# ioADuCM302x register map
Registers are 16-bit, access not given, no defined reset value unless marked. A register's access mark holds for its fields unless they carry their own. Addresses are absolute; registers are grouped by the start of their names; [hi:lo] are bit positions; {n}, {i} and the like mark numbered series.

## RTC1
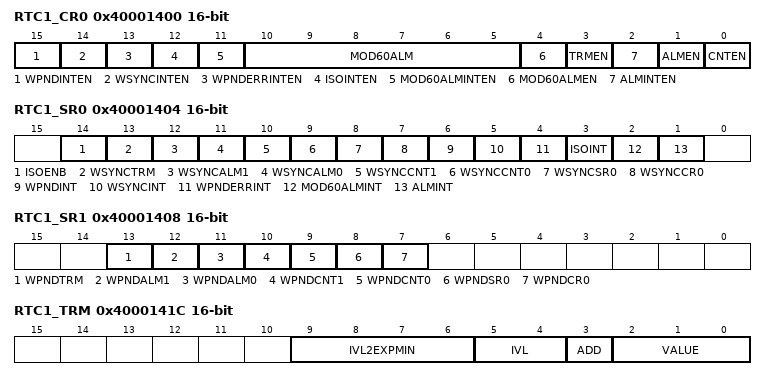
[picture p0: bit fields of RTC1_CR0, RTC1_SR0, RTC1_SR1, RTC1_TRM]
0x40001400 RTC1_CR0
  [15] WPNDINTEN, [14] WSYNCINTEN, [13] WPNDERRINTEN, [12] ISOINTEN, [11] MOD60ALMINTEN, [10:5] MOD60ALM, [4] MOD60ALMEN, [3] TRMEN, [2] ALMINTEN, [1] ALMEN, [0] CNTEN
0x40001404 RTC1_SR0
  [14] ISOENB, [13] WSYNCTRM, [12] WSYNCALM1, [11] WSYNCALM0, [10] WSYNCCNT1, [9] WSYNCCNT0, [8] WSYNCSR0, [7] WSYNCCR0, [6] WPNDINT, [5] WSYNCINT, [4] WPNDERRINT, [3] ISOINT, [2] MOD60ALMINT, [1] ALMINT
0x40001408 RTC1_SR1
  [13] WPNDTRM, [12] WPNDALM1, [11] WPNDALM0, [10] WPNDCNT1, [9] WPNDCNT0, [8] WPNDSR0, [7] WPNDCR0
0x4000140C RTC1_CNT0
0x40001410 RTC1_CNT1
0x40001414 RTC1_ALM0
0x40001418 RTC1_ALM1
0x4000141C RTC1_TRM
  [9:6] IVL2EXPMIN, [5:4] IVL, [3] ADD, [2:0] VALUE
0x40001420 RTC1_GWY
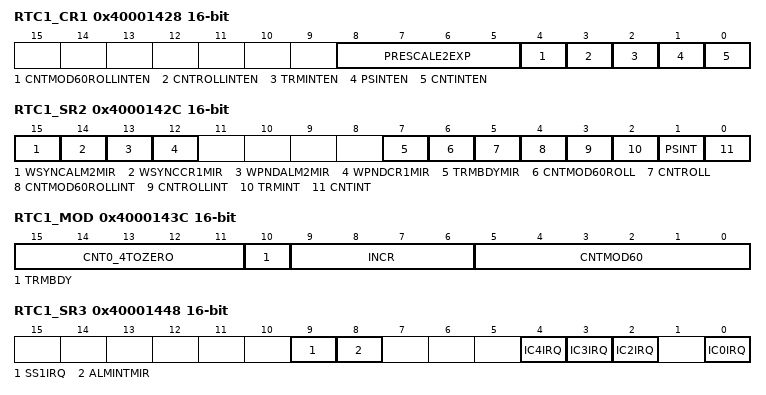
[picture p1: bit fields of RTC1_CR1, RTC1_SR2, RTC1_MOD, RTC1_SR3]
0x40001428 RTC1_CR1
  [8:5] PRESCALE2EXP, [4] CNTMOD60ROLLINTEN, [3] CNTROLLINTEN, [2] TRMINTEN, [1] PSINTEN, [0] CNTINTEN
0x4000142C RTC1_SR2
  [15] WSYNCALM2MIR, [14] WSYNCCR1MIR, [13] WPNDALM2MIR, [12] WPNDCR1MIR, [7] TRMBDYMIR, [6] CNTMOD60ROLL, [5] CNTROLL, [4] CNTMOD60ROLLINT, [3] CNTROLLINT, [2] TRMINT, [1] PSINT, [0] CNTINT
0x40001430 RTC1_SNAP0
0x40001434 RTC1_SNAP1
0x40001438 RTC1_SNAP2
  [14:0] VALUE
0x4000143C RTC1_MOD
  [15:11] CNT0_4TOZERO, [10] TRMBDY, [9:6] INCR, [5:0] CNTMOD60
0x40001440 RTC1_CNT2
  [14:0] VALUE
0x40001444 RTC1_ALM2
  [14:0] VALUE
0x40001448 RTC1_SR3
  [9] SS1IRQ, [8] ALMINTMIR, [4] IC4IRQ, [3] IC3IRQ, [2] IC2IRQ, [0] IC0IRQ
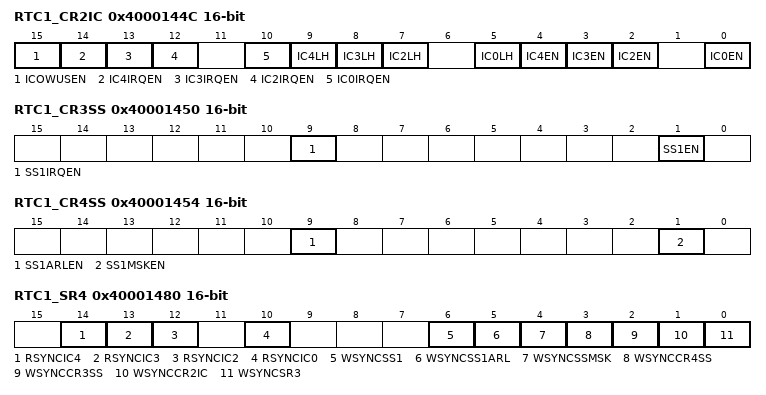
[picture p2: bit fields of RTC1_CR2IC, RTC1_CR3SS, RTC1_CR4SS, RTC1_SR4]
0x4000144C RTC1_CR2IC
  [15] ICOWUSEN, [14] IC4IRQEN, [13] IC3IRQEN, [12] IC2IRQEN, [10] IC0IRQEN, [9] IC4LH, [8] IC3LH, [7] IC2LH, [5] IC0LH, [4] IC4EN, [3] IC3EN, [2] IC2EN, [0] IC0EN
0x40001450 RTC1_CR3SS
  [9] SS1IRQEN, [1] SS1EN
0x40001454 RTC1_CR4SS
  [9] SS1ARLEN, [1] SS1MSKEN
0x40001458 RTC1_SSMSK
0x4000145C RTC1_SS1ARL
{0x4000145C+4i} RTC1_IC{i} (i=2..4)
0x40001470 RTC1_SS1
0x40001480 RTC1_SR4
  [14] RSYNCIC4, [13] RSYNCIC3, [12] RSYNCIC2, [10] RSYNCIC0, [6] WSYNCSS1, [5] WSYNCSS1ARL, [4] WSYNCSSMSK, [3] WSYNCCR4SS, [2] WSYNCCR3SS, [1] WSYNCCR2IC, [0] WSYNCSR3
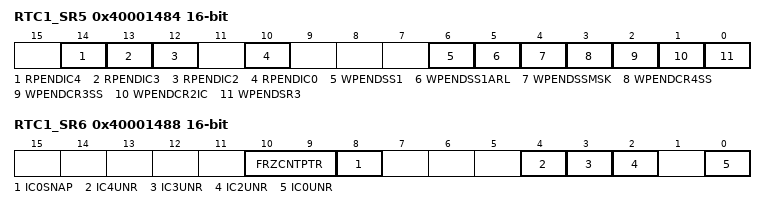
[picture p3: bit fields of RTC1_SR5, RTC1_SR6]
0x40001484 RTC1_SR5
  [14] RPENDIC4, [13] RPENDIC3, [12] RPENDIC2, [10] RPENDIC0, [6] WPENDSS1, [5] WPENDSS1ARL, [4] WPENDSSMSK, [3] WPENDCR4SS, [2] WPENDCR3SS, [1] WPENDCR2IC, [0] WPENDSR3
0x40001488 RTC1_SR6
  [10:9] FRZCNTPTR, [8] IC0SNAP, [4] IC4UNR, [3] IC3UNR, [2] IC2UNR, [0] IC0UNR
0x4000148C RTC1_SS1TGT
0x40001490 RTC1_FRZCNT

## SYS
0x40002020 SYS_ADIID
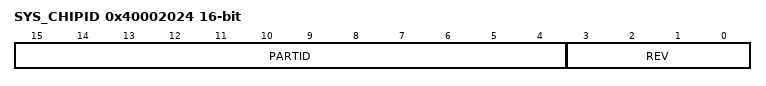
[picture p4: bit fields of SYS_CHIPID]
0x40002024 SYS_CHIPID
  [15:4] PARTID, [3:0] REV
0x40002040 SYS_SWDEN

## WDT0
0x40002C00 WDT0_LOAD
0x40002C04 WDT0_CCNT
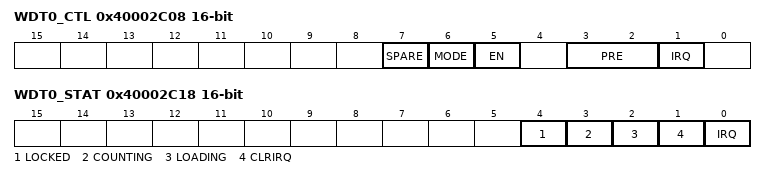
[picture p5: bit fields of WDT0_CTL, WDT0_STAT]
0x40002C08 WDT0_CTL
  [7] SPARE, [6] MODE, [5] EN, [3:2] PRE, [1] IRQ
0x40002C0C WDT0_RESTART
0x40002C18 WDT0_STAT
  [4] LOCKED, [3] COUNTING, [2] LOADING, [1] CLRIRQ, [0] IRQ

## I2C0
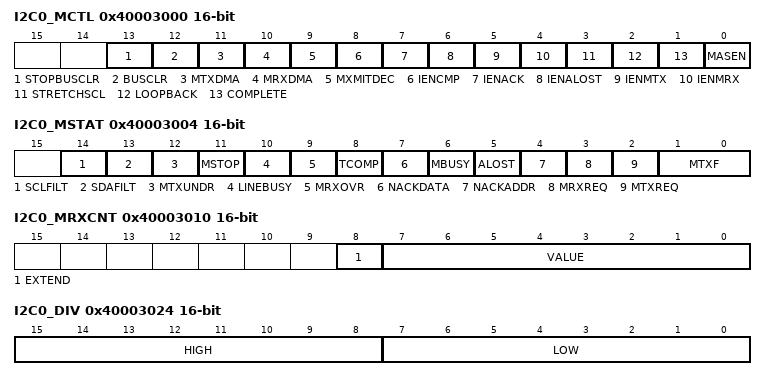
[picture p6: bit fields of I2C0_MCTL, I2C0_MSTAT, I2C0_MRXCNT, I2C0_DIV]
0x40003000 I2C0_MCTL
  [13] STOPBUSCLR, [12] BUSCLR, [11] MTXDMA, [10] MRXDMA, [9] MXMITDEC, [8] IENCMP, [7] IENACK, [6] IENALOST, [5] IENMTX, [4] IENMRX, [3] STRETCHSCL, [2] LOOPBACK, [1] COMPLETE, [0] MASEN
0x40003004 I2C0_MSTAT
  [14] SCLFILT, [13] SDAFILT, [12] MTXUNDR, [11] MSTOP, [10] LINEBUSY, [9] MRXOVR, [8] TCOMP, [7] NACKDATA, [6] MBUSY, [5] ALOST, [4] NACKADDR, [3] MRXREQ, [2] MTXREQ, [1:0] MTXF
0x40003008 I2C0_MRX
  [7:0] VALUE
0x4000300C I2C0_MTX
  [7:0] VALUE
0x40003010 I2C0_MRXCNT
  [8] EXTEND, [7:0] VALUE
0x40003014 I2C0_MCRXCNT
  [7:0] VALUE
0x40003018 I2C0_ADDR1
  [7:0] VALUE
0x4000301C I2C0_ADDR2
  [7:0] VALUE
0x40003020 I2C0_BYT
  [7:0] SBYTE
0x40003024 I2C0_DIV
  [15:8] HIGH, [7:0] LOW
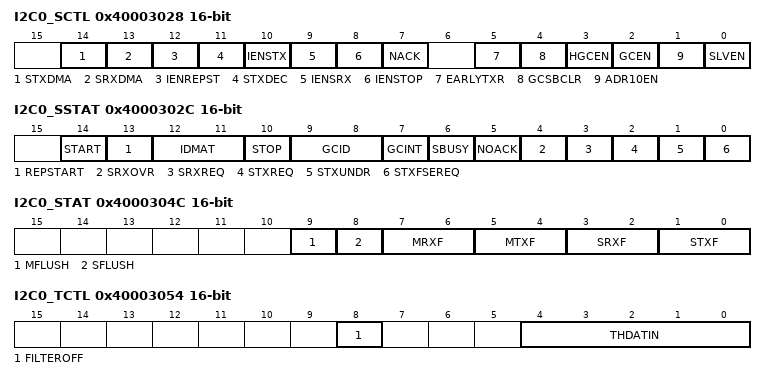
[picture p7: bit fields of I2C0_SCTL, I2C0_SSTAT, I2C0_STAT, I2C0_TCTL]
0x40003028 I2C0_SCTL
  [14] STXDMA, [13] SRXDMA, [12] IENREPST, [11] STXDEC, [10] IENSTX, [9] IENSRX, [8] IENSTOP, [7] NACK, [5] EARLYTXR, [4] GCSBCLR, [3] HGCEN, [2] GCEN, [1] ADR10EN, [0] SLVEN
0x4000302C I2C0_SSTAT
  [14] START, [13] REPSTART, [12:11] IDMAT, [10] STOP, [9:8] GCID, [7] GCINT, [6] SBUSY, [5] NOACK, [4] SRXOVR, [3] SRXREQ, [2] STXREQ, [1] STXUNDR, [0] STXFSEREQ
0x40003030 I2C0_SRX
  [7:0] VALUE
0x40003034 I2C0_STX
  [7:0] VALUE
0x40003038 I2C0_ALT
  [7:0] ID
{0x4000303C+4i} I2C0_ID{i} (i=0..3)
  [7:0] VALUE
0x4000304C I2C0_STAT
  [9] MFLUSH, [8] SFLUSH, [7:6] MRXF, [5:4] MTXF, [3:2] SRXF, [1:0] STXF
0x40003050 I2C0_SHCTL
  [0] RST
0x40003054 I2C0_TCTL
  [8] FILTEROFF, [4:0] THDATIN
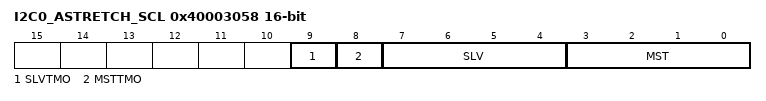
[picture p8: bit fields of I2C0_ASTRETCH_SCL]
0x40003058 I2C0_ASTRETCH_SCL
  [9] SLVTMO, [8] MSTTMO, [7:4] SLV, [3:0] MST
